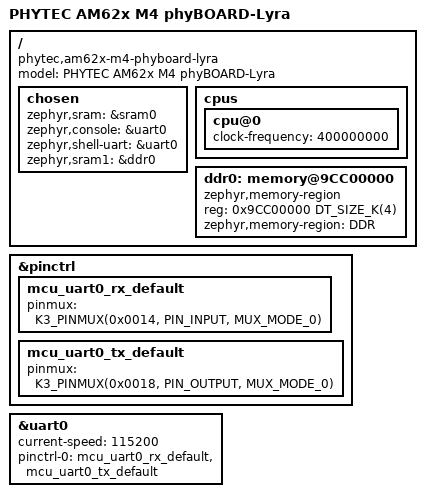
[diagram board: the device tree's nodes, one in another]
/*
 * Copyright (C) 2023 PHYTEC Messtechnik GmbH
 * Author: Daniel Schultz <d.schultz@phytec.de>
 *
 * SPDX-License-Identifier: Apache-2.0
 */

/dts-v1/;

#include <ti/am62x_m4.dtsi>

/ {
	model = "PHYTEC AM62x M4 phyBOARD-Lyra";
	compatible = "phytec,am62x-m4-phyboard-lyra", "ti,am625";

	chosen {
		zephyr,sram = &sram0;
		zephyr,console = &uart0;
		zephyr,shell-uart = &uart0;
		zephyr,sram1 = &ddr0;
	};

	cpus {
		cpu@0 {
			status = "okay";
			clock-frequency = <400000000>;
		};
	};

	ddr0:memory@9CC00000{
		compatible = "zephyr,memory-region", "mmio-sram";
		reg = <0x9CC00000 DT_SIZE_K(4)>;
		zephyr,memory-region = "DDR";
	};
};

&pinctrl {
	mcu_uart0_rx_default: mcu_uart0_rx_default {
		pinmux = <K3_PINMUX(0x0014, PIN_INPUT, MUX_MODE_0)>;
	};
	mcu_uart0_tx_default: mcu_uart0_tx_default {
		pinmux = <K3_PINMUX(0x0018, PIN_OUTPUT, MUX_MODE_0)>;
	};
};

&uart0 {
	current-speed = <115200>;
	pinctrl-0 = <&mcu_uart0_rx_default &mcu_uart0_tx_default>;
	pinctrl-names = "default";
	status = "okay";
};
